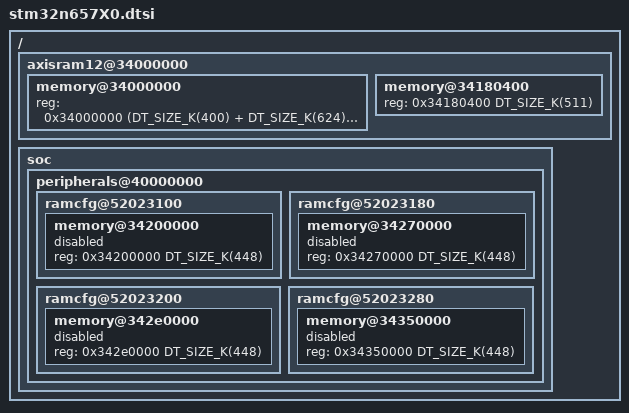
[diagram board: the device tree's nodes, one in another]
/*
 * Copyright (c) 2024 STMicroelectronics
 *
 * SPDX-License-Identifier: Apache-2.0
 */
#include <st/n6/stm32n657.dtsi>
#include <mem.h>

/ {
	axisram12@34000000 {
		memory@34000000 {
			/* This section is the RAM available to the chainloaded application */
			/* 400 kB of FLEXRAM followed by 624 kB of AXISRAM1 + AXISRAM2 */
			reg = <0x34000000 (DT_SIZE_K(400) + DT_SIZE_K(624) + DT_SIZE_M(1))>;
		};

		memory@34180400 {
			/* This section is the RAM available to FSBL application */
			reg = <0x34180400 DT_SIZE_K(511)>;
		};
	};

	soc {
		peripherals@40000000 {
			ramcfg@52023100 {
				memory@34200000 {
					reg = <0x34200000 DT_SIZE_K(448)>;
					status = "disabled";
				};
			};

			ramcfg@52023180 {
				memory@34270000 {
					reg = <0x34270000 DT_SIZE_K(448)>;
					status = "disabled";
				};
			};

			ramcfg@52023200 {
				memory@342e0000 {
					reg = <0x342e0000 DT_SIZE_K(448)>;
					status = "disabled";
				};
			};

			ramcfg@52023280 {
				memory@34350000 {
					reg = <0x34350000 DT_SIZE_K(448)>;
					status = "disabled";
				};
			};
		};
	};
};
